# N572F072_v3 register map
File version: 1.0
Registers are 32-bit, read-write, reset 0x0 unless marked. A register's access mark holds for its fields unless they carry their own. Offsets are from the block's base; [hi:lo] are bit positions; {n}, {i} and the like mark numbered series.

## SCS — SCS Register Map
Base 0xE000E000
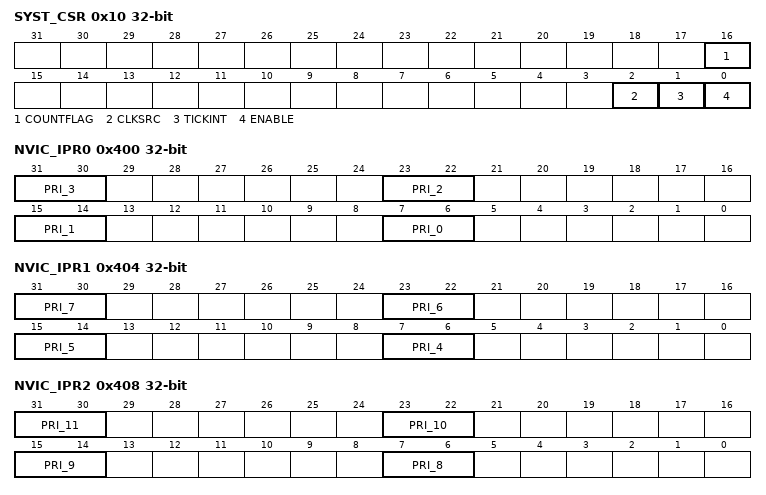
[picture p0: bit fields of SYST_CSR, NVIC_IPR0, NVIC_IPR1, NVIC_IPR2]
0x10 SYST_CSR — SysTick Control and Status Register
  [16] COUNTFLAG — System Tick Count Flag. Returns 1 if timer counted to 0 since last time this register was read.
    0=Cleared on read or by a write to the Current Value register; 1=Set by a count transition from 1 to 0
  [2] CLKSRC — System Tick Clock Source Selection. If no external clock provided, this bit will read as 1 and ignore writes.
    0=clock source is (optional) external reference clock; 1=core clock used for SysTick
  [1] TICKINT — Enables SYST Exception Request
    0=Counting down to 0 does not cause the SysTick exception to be pended. Software can use COUNTFLAG to determine if a count to zero has occurred; 1=Counting down to 0 will cause SysTick exception to be pended. Clearing the SysTick current value register by a register write in software will not cause SysTick to be pended
  [0] ENABLE — System Tick Counter Enabled
    0=The counter is disabled; 1=The counter will operate in a multi-shot manner
0x14 SYST_RVR reset not defined — SysTick Reload Value Register
  [23:0] RELOAD — System Tick Reload Value. Value to load into the Current Value register when the counter reaches 0. To generate a multi-shot timer with a period of N processor clock cycles, use a RELOAD value of N-1. For example, if the SysTick interrupt is required every 200 clock pulses, set RELOAD to 199.
0x18 SYST_CVR reset not defined — SysTick Current Value Register
  [23:0] CURRENT — System Tick Current Counter Value. This is the value of the counter at the time it is sampled. The counter does not provide read-modify-write protection. The register is write-clear. A software write of any value will clear the register to 0.
0x100 NVIC_ISER — IRQ0 ~ IRQ15 Set-Enable Control Register
  [15:0] SETENA — Interrupt Set-Enable Bit. The NVIC_ISER register enables interrupts, and shows what interrupts are enabled. Each bit represents an interrupt number from IRQ0 ~ IRQ15 (Vector number from 16 ~ 31). . Write Operation:
    0=No effect. Interrupt Disabled; 1=Interrupt Enabled
0x180 NVIC_ICER — IRQ0 ~ IRQ15 Clear-Enable Control Register
  [15:0] CLRENA — Interrupt Clear-Enable Bit. The NVIC_ICER register disables interrupts, and shows what interrupts are enabled. Each bit represents an interrupt number from IRQ0 ~ IRQ15 (Vector number from 16 ~ 31). . Write Operation:
    0=No effect. Interrupt Disabled; 1=Interrupt Disabled. Interrupt Enabled
0x200 NVIC_ISPR — IRQ0 ~ IRQ15 Set-Pending Control Register
  [15:0] SETPEND — Interrupt Set-Pending Bit. The NVIC_ISPR register forces interrupts into the pending state, and shows what interrupts are pending. Each bit represents an interrupt number from IRQ0 ~ IRQ15 (Vector number from 16 ~ 31). . Write Operation:
    0=No effect. Interrupt is not pending; 1=Changes interrupt state to pending. Interrupt is pending
0x280 NVIC_ICPR — IRQ0 ~ IRQ15 Clear-Pending Control Register
  [15:0] CLRPEND — Interrupt Clear-Pending Bit. The NVIC_ICPR register removes the pending state of associated interrupts, and shows what interrupts are pending. Each bit represents an interrupt number from IRQ0 ~ IRQ15 (Vector number from 16 ~ 31). Write Operation:
    0=No effect. Interrupt is not pending; 1=Removes pending state of an interrupt. Interrupt is pending
0x400 NVIC_IPR0 — IRQ0 ~ IRQ3 Priority Control Register
  [8n+7:8n+6] PRI_{n} (n=0..3) — Priority Of IRQ{n} "0" denotes the highest priority and "3" denotes lowest priority
0x404 NVIC_IPR1 — IRQ4 ~ IRQ7 Priority Control Register
  [8n-25:8n-26] PRI_{n} (n=4..7) — Priority Of IRQ{n} "0" denotes the highest priority and "3" denotes lowest priority
0x408 NVIC_IPR2 — IRQ8 ~ IRQ11 Priority Control Register
  [8n-57:8n-58] PRI_{n} (n=8..11) — Priority Of IRQ{n} "0" denotes the highest priority and "3" denotes lowest priority
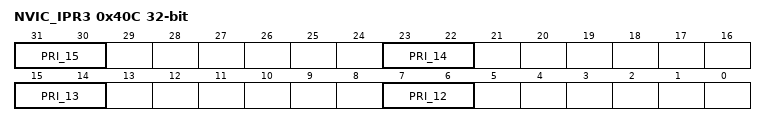
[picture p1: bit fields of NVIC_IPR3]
0x40C NVIC_IPR3 — IRQ12 ~ IRQ15 Priority Control Register
  [8n-89:8n-90] PRI_{n} (n=12..15) — Priority Of IRQ{n} "0" denotes the highest priority and "3" denotes lowest priority
